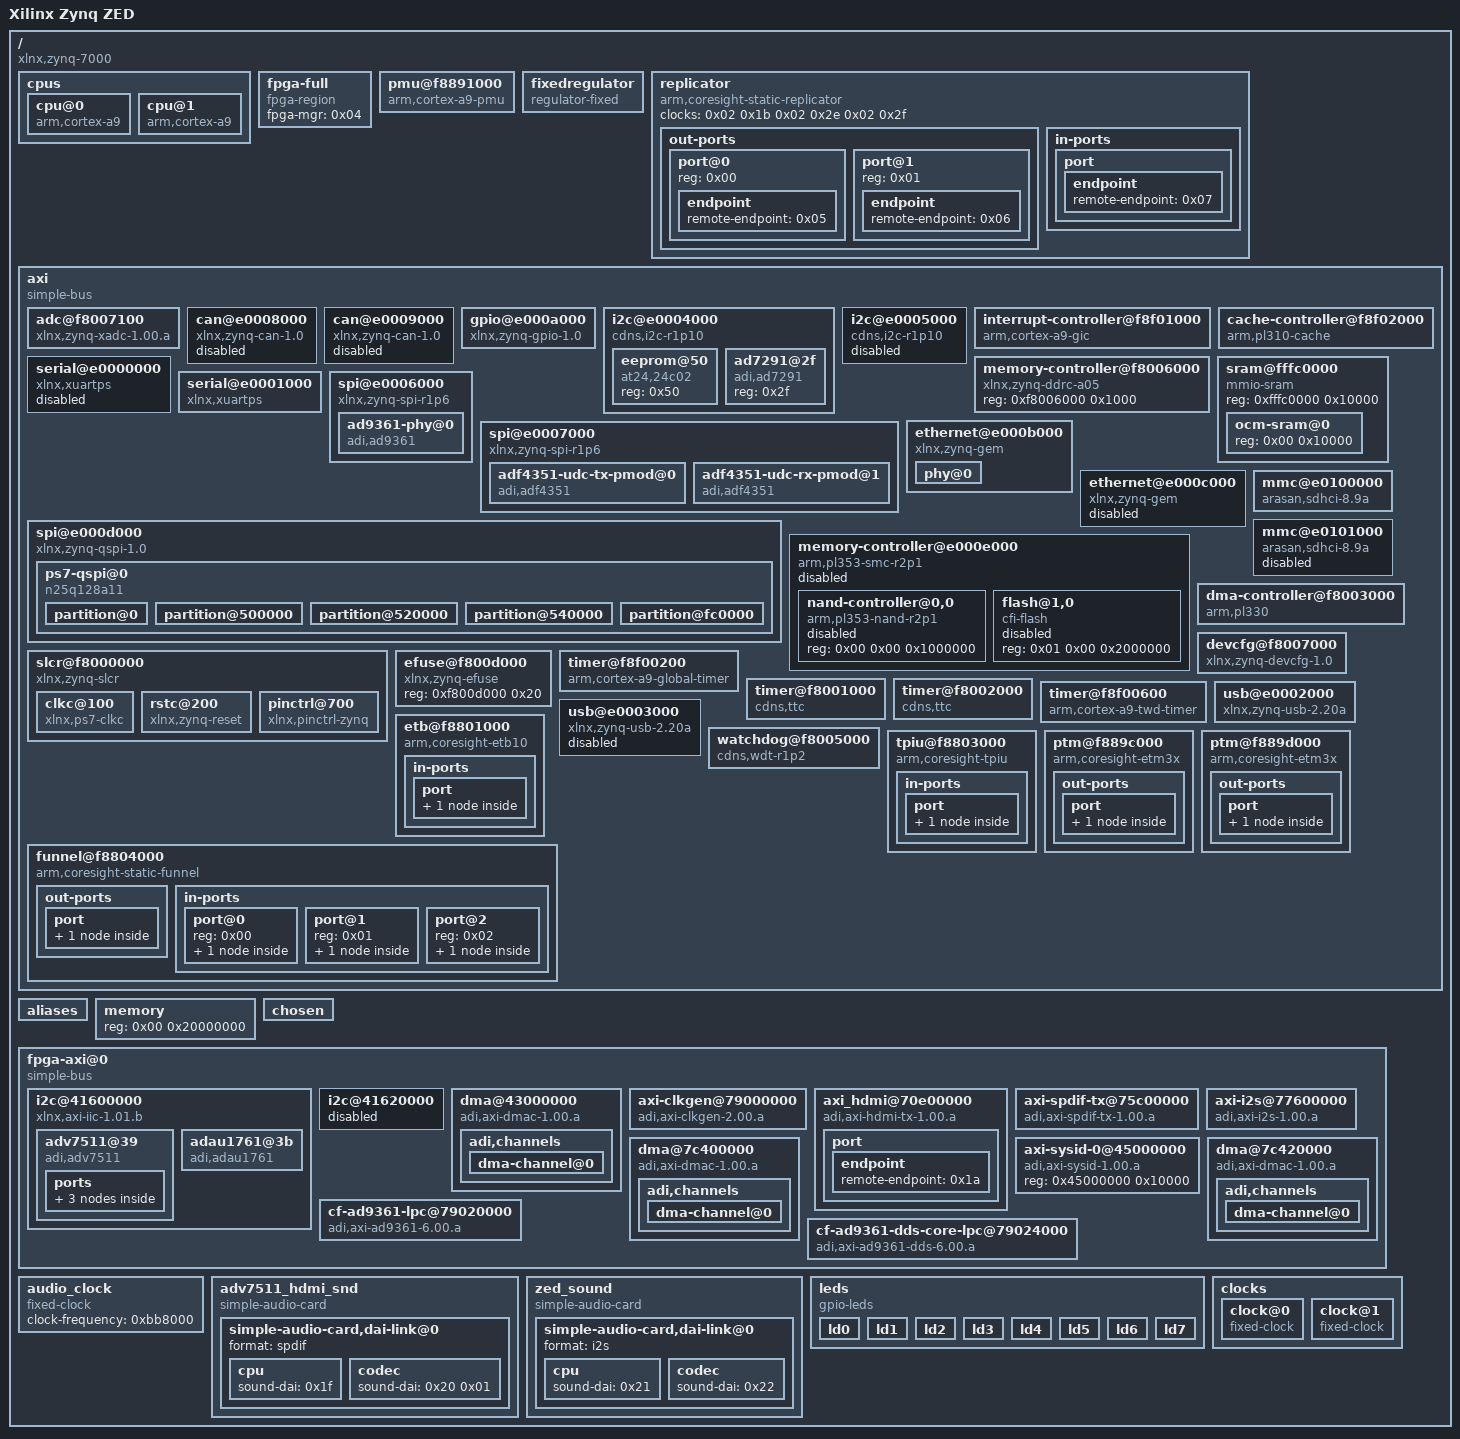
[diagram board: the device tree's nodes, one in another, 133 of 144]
/dts-v1/;

/ {
	#address-cells = <0x01>;
	#size-cells = <0x01>;
	compatible = "xlnx,zynq-7000";
	interrupt-parent = <0x01>;
	model = "Xilinx Zynq ZED";

	cpus {
		#address-cells = <0x01>;
		#size-cells = <0x00>;

		cpu@0 {
			compatible = "arm,cortex-a9";
			device_type = "cpu";
			reg = <0x00>;
			clocks = <0x02 0x03>;
			clock-latency = <0x3e8>;
			cpu0-supply = <0x03>;
			operating-points = <0xa2c2b 0xf4240 0x51616 0xf4240>;
			phandle = <0x12>;
		};

		cpu@1 {
			compatible = "arm,cortex-a9";
			device_type = "cpu";
			reg = <0x01>;
			clocks = <0x02 0x03>;
			phandle = <0x14>;
		};
	};

	fpga-full {
		compatible = "fpga-region";
		fpga-mgr = <0x04>;
		#address-cells = <0x01>;
		#size-cells = <0x01>;
		ranges;
		phandle = <0x23>;
	};

	pmu@f8891000 {
		compatible = "arm,cortex-a9-pmu";
		interrupts = <0x00 0x05 0x04 0x00 0x06 0x04>;
		interrupt-parent = <0x01>;
		reg = <0xf8891000 0x1000 0xf8893000 0x1000>;
	};

	fixedregulator {
		compatible = "regulator-fixed";
		regulator-name = "VCCPINT";
		regulator-min-microvolt = <0xf4240>;
		regulator-max-microvolt = <0xf4240>;
		regulator-boot-on;
		regulator-always-on;
		phandle = <0x03>;
	};

	replicator {
		compatible = "arm,coresight-static-replicator";
		clocks = <0x02 0x1b 0x02 0x2e 0x02 0x2f>;
		clock-names = "apb_pclk", "dbg_trc", "dbg_apb";

		out-ports {
			#address-cells = <0x01>;
			#size-cells = <0x00>;

			port@0 {
				reg = <0x00>;

				endpoint {
					remote-endpoint = <0x05>;
					phandle = <0x0e>;
				};
			};

			port@1 {
				reg = <0x01>;

				endpoint {
					remote-endpoint = <0x06>;
					phandle = <0x0d>;
				};
			};
		};

		in-ports {

			port {

				endpoint {
					remote-endpoint = <0x07>;
					phandle = <0x0f>;
				};
			};
		};
	};

	axi {
		u-boot,dm-pre-reloc;
		compatible = "simple-bus";
		#address-cells = <0x01>;
		#size-cells = <0x01>;
		interrupt-parent = <0x01>;
		ranges;
		phandle = <0x24>;

		adc@f8007100 {
			compatible = "xlnx,zynq-xadc-1.00.a";
			reg = <0xf8007100 0x20>;
			interrupts = <0x00 0x07 0x04>;
			interrupt-parent = <0x01>;
			clocks = <0x02 0x0c>;
			phandle = <0x25>;
		};

		can@e0008000 {
			compatible = "xlnx,zynq-can-1.0";
			status = "disabled";
			clocks = <0x02 0x13 0x02 0x24>;
			clock-names = "can_clk", "pclk";
			reg = <0xe0008000 0x1000>;
			interrupts = <0x00 0x1c 0x04>;
			interrupt-parent = <0x01>;
			tx-fifo-depth = <0x40>;
			rx-fifo-depth = <0x40>;
			phandle = <0x26>;
		};

		can@e0009000 {
			compatible = "xlnx,zynq-can-1.0";
			status = "disabled";
			clocks = <0x02 0x14 0x02 0x25>;
			clock-names = "can_clk", "pclk";
			reg = <0xe0009000 0x1000>;
			interrupts = <0x00 0x33 0x04>;
			interrupt-parent = <0x01>;
			tx-fifo-depth = <0x40>;
			rx-fifo-depth = <0x40>;
			phandle = <0x27>;
		};

		gpio@e000a000 {
			compatible = "xlnx,zynq-gpio-1.0";
			#gpio-cells = <0x02>;
			clocks = <0x02 0x2a>;
			gpio-controller;
			interrupt-controller;
			#interrupt-cells = <0x02>;
			interrupt-parent = <0x01>;
			interrupts = <0x00 0x14 0x04>;
			reg = <0xe000a000 0x1000>;
			phandle = <0x09>;
		};

	/*	i2c@e0004000 {
			compatible = "cdns,i2c-r1p10";
			status = "disabled";
			clocks = <0x02 0x26>;
			interrupt-parent = <0x01>;
			interrupts = <0x00 0x19 0x04>;
			clock-frequency = <0x61a80>;
			reg = <0xe0004000 0x1000>;
			#address-cells = <0x01>;
			#size-cells = <0x00>;
			phandle = <0x28>;
		}; */
            
                i2c@e0004000 {
                         compatible = "cdns,i2c-r1p10";
        		status = "okay";
        		clocks = <0x02 0x26>;
        		interrupt-parent = <0x01>;
        		interrupts = <0x00 0x19 0x04>;
        		clock-frequency = <100000>;
        		reg = <0xe0004000 0x1000>;
        		#address-cells = <0x01>;
       			 #size-cells = <0x00>;
        		phandle = <0x28>;

                      #address-cells = <1>;
                     #size-cells = <0>;

                      eeprom@50 {
                         compatible = "at24,24c02";
                         reg = <0x50>;
                         };

    			ad7291@2f {
      			  compatible = "adi,ad7291";
       			 reg = <0x2f>;
   			 };
			 };

		i2c@e0005000 {
			compatible = "cdns,i2c-r1p10";
			status = "disabled";
			clocks = <0x02 0x27>;
			interrupt-parent = <0x01>;
			interrupts = <0x00 0x30 0x04>;
			clock-frequency = <0x61a80>;
			reg = <0xe0005000 0x1000>;
			#address-cells = <0x01>;
			#size-cells = <0x00>;
			phandle = <0x29>;
		};

		interrupt-controller@f8f01000 {
			compatible = "arm,cortex-a9-gic";
			#interrupt-cells = <0x03>;
			interrupt-controller;
			reg = <0xf8f01000 0x1000 0xf8f00100 0x100>;
			phandle = <0x01>;
		};

		cache-controller@f8f02000 {
			compatible = "arm,pl310-cache";
			reg = <0xf8f02000 0x1000>;
			interrupts = <0x00 0x02 0x04>;
			arm,data-latency = <0x03 0x02 0x02>;
			arm,tag-latency = <0x02 0x02 0x02>;
			cache-unified;
			cache-level = <0x02>;
			phandle = <0x2a>;
		};

		memory-controller@f8006000 {
			compatible = "xlnx,zynq-ddrc-a05";
			reg = <0xf8006000 0x1000>;
			phandle = <0x2b>;
		};

		sram@fffc0000 {
			compatible = "mmio-sram";
			reg = <0xfffc0000 0x10000>;
			#address-cells = <0x01>;
			#size-cells = <0x01>;
			ranges = <0x00 0xfffc0000 0x10000>;
			phandle = <0x2c>;

			ocm-sram@0 {
				reg = <0x00 0x10000>;
			};
		};

		serial@e0000000 {
			compatible = "xlnx,xuartps", "cdns,uart-r1p8";
			status = "disabled";
			clocks = <0x02 0x17 0x02 0x28>;
			clock-names = "uart_clk", "pclk";
			reg = <0xe0000000 0x1000>;
			interrupts = <0x00 0x1b 0x04>;
			phandle = <0x2d>;
		};

		serial@e0001000 {
			compatible = "xlnx,xuartps", "cdns,uart-r1p8";
			status = "okay";
			clocks = <0x02 0x18 0x02 0x29>;
			clock-names = "uart_clk", "pclk";
			reg = <0xe0001000 0x1000>;
			interrupts = <0x00 0x32 0x04>;
			phandle = <0x2e>;
		};

		spi@e0006000 {
			compatible = "xlnx,zynq-spi-r1p6";
			reg = <0xe0006000 0x1000>;
			status = "okay";
			interrupt-parent = <0x01>;
			interrupts = <0x00 0x1a 0x04>;
			clocks = <0x02 0x19 0x02 0x22>;
			clock-names = "ref_clk", "pclk";
			#address-cells = <0x01>;
			#size-cells = <0x00>;
			phandle = <0x2f>;

			ad9361-phy@0 {
				compatible = "adi,ad9361";
				reg = <0x00>;
				spi-cpha;
				spi-max-frequency = <0x989680>;
				clocks = <0x08 0x00>;
				clock-names = "ad9361_ext_refclk";
				clock-output-names = "rx_sampl_clk", "tx_sampl_clk";
				#clock-cells = <0x01>;
				adi,digital-interface-tune-skip-mode = <0x00>;
				adi,pp-tx-swap-enable;
				adi,pp-rx-swap-enable;
				adi,rx-frame-pulse-mode-enable;
				adi,lvds-mode-enable;
				adi,lvds-bias-mV = <0x96>;
				adi,lvds-rx-onchip-termination-enable;
				adi,rx-data-delay = <0x04>;
				adi,tx-fb-clock-delay = <0x07>;
				adi,dcxo-coarse-and-fine-tune = <0x08 0x1720>;
				adi,2rx-2tx-mode-enable;
				adi,frequency-division-duplex-mode-enable;
				adi,rx-rf-port-input-select = <0x00>;
				adi,tx-rf-port-input-select = <0x00>;
				adi,tx-attenuation-mdB = <0x2710>;
				adi,tx-lo-powerdown-managed-enable;
				adi,rf-rx-bandwidth-hz = <0x112a880>;
				adi,rf-tx-bandwidth-hz = <0x112a880>;
				adi,rx-synthesizer-frequency-hz = <0x00 0x8f0d1800>;
				adi,tx-synthesizer-frequency-hz = <0x00 0x92080880>;
				adi,rx-path-clock-frequencies = <0x3a980000 0xea60000 0x7530000 0x3a98000 0x1d4c000 0x1d4c000>;
				adi,tx-path-clock-frequencies = <0x3a980000 0x7530000 0x7530000 0x3a98000 0x1d4c000 0x1d4c000>;
				adi,gc-rx1-mode = <0x02>;
				adi,gc-rx2-mode = <0x02>;
				adi,gc-adc-ovr-sample-size = <0x04>;
				adi,gc-adc-small-overload-thresh = <0x2f>;
				adi,gc-adc-large-overload-thresh = <0x3a>;
				adi,gc-lmt-overload-high-thresh = <0x320>;
				adi,gc-lmt-overload-low-thresh = <0x2c0>;
				adi,gc-dec-pow-measurement-duration = <0x2000>;
				adi,gc-low-power-thresh = <0x18>;
				adi,mgc-inc-gain-step = <0x02>;
				adi,mgc-dec-gain-step = <0x02>;
				adi,mgc-split-table-ctrl-inp-gain-mode = <0x00>;
				adi,agc-attack-delay-extra-margin-us = <0x01>;
				adi,agc-outer-thresh-high = <0x05>;
				adi,agc-outer-thresh-high-dec-steps = <0x02>;
				adi,agc-inner-thresh-high = <0x0a>;
				adi,agc-inner-thresh-high-dec-steps = <0x01>;
				adi,agc-inner-thresh-low = <0x0c>;
				adi,agc-inner-thresh-low-inc-steps = <0x01>;
				adi,agc-outer-thresh-low = <0x12>;
				adi,agc-outer-thresh-low-inc-steps = <0x02>;
				adi,agc-adc-small-overload-exceed-counter = <0x0a>;
				adi,agc-adc-large-overload-exceed-counter = <0x0a>;
				adi,agc-adc-large-overload-inc-steps = <0x02>;
				adi,agc-lmt-overload-large-exceed-counter = <0x0a>;
				adi,agc-lmt-overload-small-exceed-counter = <0x0a>;
				adi,agc-lmt-overload-large-inc-steps = <0x02>;
				adi,agc-gain-update-interval-us = <0x3e8>;
				adi,fagc-dec-pow-measurement-duration = <0x40>;
				adi,fagc-lp-thresh-increment-steps = <0x01>;
				adi,fagc-lp-thresh-increment-time = <0x05>;
				adi,fagc-energy-lost-stronger-sig-gain-lock-exit-cnt = <0x08>;
				adi,fagc-final-overrange-count = <0x03>;
				adi,fagc-gain-index-type-after-exit-rx-mode = <0x00>;
				adi,fagc-lmt-final-settling-steps = <0x01>;
				adi,fagc-lock-level = <0x0a>;
				adi,fagc-lock-level-gain-increase-upper-limit = <0x05>;
				adi,fagc-lock-level-lmt-gain-increase-enable;
				adi,fagc-lpf-final-settling-steps = <0x01>;
				adi,fagc-optimized-gain-offset = <0x05>;
				adi,fagc-power-measurement-duration-in-state5 = <0x40>;
				adi,fagc-rst-gla-engergy-lost-goto-optim-gain-enable;
				adi,fagc-rst-gla-engergy-lost-sig-thresh-below-ll = <0x0a>;
				adi,fagc-rst-gla-engergy-lost-sig-thresh-exceeded-enable;
				adi,fagc-rst-gla-if-en-agc-pulled-high-mode = <0x00>;
				adi,fagc-rst-gla-large-adc-overload-enable;
				adi,fagc-rst-gla-large-lmt-overload-enable;
				adi,fagc-rst-gla-stronger-sig-thresh-above-ll = <0x0a>;
				adi,fagc-rst-gla-stronger-sig-thresh-exceeded-enable;
				adi,fagc-state-wait-time-ns = <0x104>;
				adi,fagc-use-last-lock-level-for-set-gain-enable;
				adi,rssi-restart-mode = <0x03>;
				adi,rssi-delay = <0x01>;
				adi,rssi-wait = <0x01>;
				adi,rssi-duration = <0x3e8>;
				adi,ctrl-outs-index = <0x00>;
				adi,ctrl-outs-enable-mask = <0xff>;
				adi,temp-sense-measurement-interval-ms = <0x3e8>;
				adi,temp-sense-offset-signed = <0xce>;
				adi,temp-sense-periodic-measurement-enable;
				adi,aux-dac-manual-mode-enable;
				adi,aux-dac1-default-value-mV = <0x00>;
				adi,aux-dac1-rx-delay-us = <0x00>;
				adi,aux-dac1-tx-delay-us = <0x00>;
				adi,aux-dac2-default-value-mV = <0x00>;
				adi,aux-dac2-rx-delay-us = <0x00>;
				adi,aux-dac2-tx-delay-us = <0x00>;
				en_agc-gpios = <0x09 0x62 0x00>;
				sync-gpios = <0x09 0x63 0x00>;
				reset-gpios = <0x09 0x64 0x00>;
				enable-gpios = <0x09 0x65 0x00>;
				txnrx-gpios = <0x09 0x66 0x00>;
				phandle = <0x1d>;
			};
		};

		spi@e0007000 {
			compatible = "xlnx,zynq-spi-r1p6";
			reg = <0xe0007000 0x1000>;
			status = "okay";
			interrupt-parent = <0x01>;
			interrupts = <0x00 0x31 0x04>;
			clocks = <0x02 0x1a 0x02 0x23>;
			clock-names = "ref_clk", "pclk";
			#address-cells = <0x01>;
			#size-cells = <0x00>;
			phandle = <0x30>;

			adf4351-udc-tx-pmod@0 {
				compatible = "adi,adf4351";
				reg = <0x00>;
				spi-max-frequency = <0x989680>;
				clocks = <0x0a>;
				clock-names = "clkin";
				adi,channel-spacing = <0xf4240>;
				adi,power-up-frequency = <0x160dc080>;
				adi,phase-detector-polarity-positive-enable;
				adi,charge-pump-current = <0x9c4>;
				adi,output-power = <0x03>;
				adi,mute-till-lock-enable;
				adi,muxout-select = <0x06>;
				gpios = <0x09 0x68 0x00>;
				phandle = <0x31>;
			};

			adf4351-udc-rx-pmod@1 {
				compatible = "adi,adf4351";
				reg = <0x01>;
				spi-max-frequency = <0x989680>;
				clocks = <0x0a>;
				clock-names = "clkin";
				adi,channel-spacing = <0xf4240>;
				adi,power-up-frequency = <0x1443fd00>;
				adi,phase-detector-polarity-positive-enable;
				adi,charge-pump-current = <0x9c4>;
				adi,output-power = <0x03>;
				adi,mute-till-lock-enable;
				adi,muxout-select = <0x06>;
				gpios = <0x09 0x67 0x00>;
				phandle = <0x32>;
			};
		};

		spi@e000d000 {
			compatible = "xlnx,zynq-qspi-1.0";
			reg = <0xe000d000 0x1000>;
			interrupt-parent = <0x01>;
			interrupts = <0x00 0x13 0x04>;
			clocks = <0x02 0x0a 0x02 0x2b>;
			clock-names = "ref_clk", "pclk";
			status = "okay";
			#address-cells = <0x01>;
			#size-cells = <0x00>;
			is-dual = <0x00>;
			num-cs = <0x01>;
			phandle = <0x33>;

			ps7-qspi@0 {
				#address-cells = <0x01>;
				#size-cells = <0x01>;
				compatible = "n25q128a11";
				reg = <0x00>;
				spi-max-frequency = <0x2faf080>;
				phandle = <0x34>;

				partition@0 {
					label = "boot";
					reg = <0x00 0x500000>;
				};

				partition@500000 {
					label = "bootenv";
					reg = <0x500000 0x20000>;
				};

				partition@520000 {
					label = "config";
					reg = <0x520000 0x20000>;
				};

				partition@540000 {
					label = "image";
					reg = <0x540000 0xa80000>;
				};

				partition@fc0000 {
					label = "spare";
					reg = <0xfc0000 0x00>;
				};
			};
		};

		ethernet@e000b000 {
			compatible = "xlnx,zynq-gem", "cdns,gem";
			reg = <0xe000b000 0x1000>;
			status = "okay";
			interrupts = <0x00 0x16 0x04>;
			clocks = <0x02 0x1e 0x02 0x1e 0x02 0x0d>;
			clock-names = "pclk", "hclk", "tx_clk";
			#address-cells = <0x01>;
			#size-cells = <0x00>;
			phy-handle = <0x0b>;
			phy-mode = "rgmii-id";
			phandle = <0x35>;

			phy@0 {
				device_type = "ethernet-phy";
				reg = <0x00>;
				marvell,reg-init = <0x03 0x10 0xff00 0x1e 0x03 0x11 0xfff0 0x0a>;
				phandle = <0x0b>;
			};
		};

		ethernet@e000c000 {
			compatible = "xlnx,zynq-gem", "cdns,gem";
			reg = <0xe000c000 0x1000>;
			status = "disabled";
			interrupts = <0x00 0x2d 0x04>;
			clocks = <0x02 0x1f 0x02 0x1f 0x02 0x0e>;
			clock-names = "pclk", "hclk", "tx_clk";
			#address-cells = <0x01>;
			#size-cells = <0x00>;
			phandle = <0x36>;
		};

		memory-controller@e000e000 {
			compatible = "arm,pl353-smc-r2p1", "arm,primecell";
			reg = <0xe000e000 0x1000>;
			status = "disabled";
			clock-names = "memclk", "apb_pclk";
			clocks = <0x02 0x0b 0x02 0x2c>;
			ranges = <0x00 0x00 0xe1000000 0x1000000 0x01 0x00 0xe2000000 0x2000000 0x02 0x00 0xe4000000 0x2000000>;
			#address-cells = <0x02>;
			#size-cells = <0x01>;
			interrupt-parent = <0x01>;
			interrupts = <0x00 0x12 0x04>;
			phandle = <0x37>;

			nand-controller@0,0 {
				compatible = "arm,pl353-nand-r2p1";
				reg = <0x00 0x00 0x1000000>;
				status = "disabled";
				#address-cells = <0x01>;
				#size-cells = <0x00>;
				phandle = <0x38>;
			};

			flash@1,0 {
				status = "disabled";
				compatible = "cfi-flash";
				reg = <0x01 0x00 0x2000000>;
				#address-cells = <0x01>;
				#size-cells = <0x01>;
				phandle = <0x39>;
			};
		};

		mmc@e0100000 {
			compatible = "arasan,sdhci-8.9a";
			status = "okay";
			clock-names = "clk_xin", "clk_ahb";
			clocks = <0x02 0x15 0x02 0x20>;
			interrupt-parent = <0x01>;
			interrupts = <0x00 0x18 0x04>;
			reg = <0xe0100000 0x1000>;
			phandle = <0x3a>;
		};

		mmc@e0101000 {
			compatible = "arasan,sdhci-8.9a";
			status = "disabled";
			clock-names = "clk_xin", "clk_ahb";
			clocks = <0x02 0x16 0x02 0x21>;
			interrupt-parent = <0x01>;
			interrupts = <0x00 0x2f 0x04>;
			reg = <0xe0101000 0x1000>;
			phandle = <0x3b>;
		};

		slcr@f8000000 {
			u-boot,dm-pre-reloc;
			#address-cells = <0x01>;
			#size-cells = <0x01>;
			compatible = "xlnx,zynq-slcr", "syscon", "simple-mfd";
			reg = <0xf8000000 0x1000>;
			ranges;
			phandle = <0x0c>;

			clkc@100 {
				u-boot,dm-pre-reloc;
				#clock-cells = <0x01>;
				compatible = "xlnx,ps7-clkc";
				fclk-enable = <0x0f>;
				clock-output-names = "armpll", "ddrpll", "iopll", "cpu_6or4x", "cpu_3or2x", "cpu_2x", "cpu_1x", "ddr2x", "ddr3x", "dci", "lqspi", "smc", "pcap", "gem0", "gem1", "fclk0", "fclk1", "fclk2", "fclk3", "can0", "can1", "sdio0", "sdio1", "uart0", "uart1", "spi0", "spi1", "dma", "usb0_aper", "usb1_aper", "gem0_aper", "gem1_aper", "sdio0_aper", "sdio1_aper", "spi0_aper", "spi1_aper", "can0_aper", "can1_aper", "i2c0_aper", "i2c1_aper", "uart0_aper", "uart1_aper", "gpio_aper", "lqspi_aper", "smc_aper", "swdt", "dbg_trc", "dbg_apb";
				reg = <0x100 0x100>;
				ps-clk-frequency = <0x1fca055>;
				phandle = <0x02>;
			};

			rstc@200 {
				compatible = "xlnx,zynq-reset";
				reg = <0x200 0x48>;
				#reset-cells = <0x01>;
				syscon = <0x0c>;
				phandle = <0x3c>;
			};

			pinctrl@700 {
				compatible = "xlnx,pinctrl-zynq";
				reg = <0x700 0x200>;
				syscon = <0x0c>;
				phandle = <0x3d>;
			};
		};

		dma-controller@f8003000 {
			compatible = "arm,pl330", "arm,primecell";
			reg = <0xf8003000 0x1000>;
			interrupt-parent = <0x01>;
			interrupts = <0x00 0x0d 0x04 0x00 0x0e 0x04 0x00 0x0f 0x04 0x00 0x10 0x04 0x00 0x11 0x04 0x00 0x28 0x04 0x00 0x29 0x04 0x00 0x2a 0x04 0x00 0x2b 0x04>;
			#dma-cells = <0x01>;
			clocks = <0x02 0x1b>;
			clock-names = "apb_pclk";
			phandle = <0x1b>;
		};

		devcfg@f8007000 {
			compatible = "xlnx,zynq-devcfg-1.0";
			reg = <0xf8007000 0x100>;
			interrupt-parent = <0x01>;
			interrupts = <0x00 0x08 0x04>;
			clocks = <0x02 0x0c 0x02 0x0f 0x02 0x10 0x02 0x11 0x02 0x12>;
			clock-names = "ref_clk", "fclk0", "fclk1", "fclk2", "fclk3";
			syscon = <0x0c>;
			phandle = <0x04>;
		};

		efuse@f800d000 {
			compatible = "xlnx,zynq-efuse";
			reg = <0xf800d000 0x20>;
			phandle = <0x3e>;
		};

		timer@f8f00200 {
			compatible = "arm,cortex-a9-global-timer";
			reg = <0xf8f00200 0x20>;
			interrupts = <0x01 0x0b 0x301>;
			interrupt-parent = <0x01>;
			clocks = <0x02 0x04>;
			phandle = <0x3f>;
		};

		timer@f8001000 {
			interrupt-parent = <0x01>;
			interrupts = <0x00 0x0a 0x04 0x00 0x0b 0x04 0x00 0x0c 0x04>;
			compatible = "cdns,ttc";
			clocks = <0x02 0x06>;
			reg = <0xf8001000 0x1000>;
			phandle = <0x40>;
		};

		timer@f8002000 {
			interrupt-parent = <0x01>;
			interrupts = <0x00 0x25 0x04 0x00 0x26 0x04 0x00 0x27 0x04>;
			compatible = "cdns,ttc";
			clocks = <0x02 0x06>;
			reg = <0xf8002000 0x1000>;
			phandle = <0x41>;
		};

		timer@f8f00600 {
			u-boot,dm-pre-reloc;
			interrupt-parent = <0x01>;
			interrupts = <0x01 0x0d 0x301>;
			compatible = "arm,cortex-a9-twd-timer";
			reg = <0xf8f00600 0x20>;
			clocks = <0x02 0x04>;
			phandle = <0x42>;
		};

		usb@e0002000 {
			compatible = "xlnx,zynq-usb-2.20a", "chipidea,usb2";
			status = "okay";
			clocks = <0x02 0x1c>;
			interrupt-parent = <0x01>;
			interrupts = <0x00 0x15 0x04>;
			reg = <0xe0002000 0x1000>;
			phy_type = "ulpi";
			dr_mode = "host";
			xlnx,phy-reset-gpio = <0x09 0x55 0x00>;
			phandle = <0x43>;
		};

		usb@e0003000 {
			compatible = "xlnx,zynq-usb-2.20a", "chipidea,usb2";
			status = "disabled";
			clocks = <0x02 0x1d>;
			interrupt-parent = <0x01>;
			interrupts = <0x00 0x2c 0x04>;
			reg = <0xe0003000 0x1000>;
			phy_type = "ulpi";
			phandle = <0x44>;
		};

		watchdog@f8005000 {
			clocks = <0x02 0x2d>;
			compatible = "cdns,wdt-r1p2";
			interrupt-parent = <0x01>;
			interrupts = <0x00 0x09 0x01>;
			reg = <0xf8005000 0x1000>;
			timeout-sec = <0x0a>;
			phandle = <0x45>;
		};

		etb@f8801000 {
			compatible = "arm,coresight-etb10", "arm,primecell";
			reg = <0xf8801000 0x1000>;
			clocks = <0x02 0x1b 0x02 0x2e 0x02 0x2f>;
			clock-names = "apb_pclk", "dbg_trc", "dbg_apb";

			in-ports {

				port {

					endpoint {
						remote-endpoint = <0x0d>;
						phandle = <0x06>;
					};
				};
			};
		};

		tpiu@f8803000 {
			compatible = "arm,coresight-tpiu", "arm,primecell";
			reg = <0xf8803000 0x1000>;
			clocks = <0x02 0x1b 0x02 0x2e 0x02 0x2f>;
			clock-names = "apb_pclk", "dbg_trc", "dbg_apb";

			in-ports {

				port {

					endpoint {
						remote-endpoint = <0x0e>;
						phandle = <0x05>;
					};
				};
			};
		};

		funnel@f8804000 {
			compatible = "arm,coresight-static-funnel", "arm,primecell";
			reg = <0xf8804000 0x1000>;
			clocks = <0x02 0x1b 0x02 0x2e 0x02 0x2f>;
			clock-names = "apb_pclk", "dbg_trc", "dbg_apb";

			out-ports {

				port {

					endpoint {
						remote-endpoint = <0x0f>;
						phandle = <0x07>;
					};
				};
			};

			in-ports {
				#address-cells = <0x01>;
				#size-cells = <0x00>;

				port@0 {
					reg = <0x00>;

					endpoint {
						remote-endpoint = <0x10>;
						phandle = <0x13>;
					};
				};

				port@1 {
					reg = <0x01>;

					endpoint {
						remote-endpoint = <0x11>;
						phandle = <0x15>;
					};
				};

				port@2 {
					reg = <0x02>;

					endpoint {
						phandle = <0x46>;
					};
				};
			};
		};

		ptm@f889c000 {
			compatible = "arm,coresight-etm3x", "arm,primecell";
			reg = <0xf889c000 0x1000>;
			clocks = <0x02 0x1b 0x02 0x2e 0x02 0x2f>;
			clock-names = "apb_pclk", "dbg_trc", "dbg_apb";
			cpu = <0x12>;

			out-ports {

				port {

					endpoint {
						remote-endpoint = <0x13>;
						phandle = <0x10>;
					};
				};
			};
		};

		ptm@f889d000 {
			compatible = "arm,coresight-etm3x", "arm,primecell";
			reg = <0xf889d000 0x1000>;
			clocks = <0x02 0x1b 0x02 0x2e 0x02 0x2f>;
			clock-names = "apb_pclk", "dbg_trc", "dbg_apb";
			cpu = <0x14>;

			out-ports {

				port {

					endpoint {
						remote-endpoint = <0x15>;
						phandle = <0x11>;
					};
				};
			};
		};
	};

	aliases {
		ethernet0 = "/axi/ethernet@e000b000";
		serial0 = "/axi/serial@e0001000";
		phandle = <0x47>;
	};

	memory {
		device_type = "memory";
		reg = <0x00 0x20000000>;
	};

	chosen {
		bootargs = "console=ttyPS0,115200 root=/dev/mmcblk0p2 rw earlyprintk rootfstype=ext4 rootwait";
		stdout-path = "/amba@0/uart@E0001000";
	};

	fpga-axi@0 {
		compatible = "simple-bus";
		#address-cells = <0x01>;
		#size-cells = <0x01>;
		ranges;
		phandle = <0x48>;

		i2c@41600000 {
			compatible = "xlnx,axi-iic-1.01.b", "xlnx,xps-iic-2.00.a";
			reg = <0x41600000 0x10000>;
			interrupt-parent = <0x01>;
			interrupts = <0x00 0x3a 0x04>;
			clocks = <0x02 0x0f>;
			clock-names = "pclk";
			#size-cells = <0x00>;
			#address-cells = <0x01>;

			adv7511@39 {
				compatible = "adi,adv7511";
				reg = <0x39 0x3f>;
				reg-names = "primary", "edid";
				adi,input-depth = <0x08>;
				adi,input-colorspace = "yuv422";
				adi,input-clock = "1x";
				adi,input-style = <0x01>;
				adi,input-justification = "right";
				adi,clock-delay = <0x00>;
				#sound-dai-cells = <0x01>;
				phandle = <0x20>;

				ports {
					#address-cells = <0x01>;
					#size-cells = <0x00>;

					port@0 {
						reg = <0x00>;

						endpoint {
							remote-endpoint = <0x16>;
							phandle = <0x1a>;
						};
					};

					port@1 {
						reg = <0x01>;
					};
				};
			};

			adau1761@3b {
				compatible = "adi,adau1761";
				reg = <0x3b>;
				clocks = <0x17>;
				clock-names = "mclk";
				#sound-dai-cells = <0x00>;
				phandle = <0x22>;
			};
		};

	/*	i2c@41620000 {
			compatible = "xlnx,axi-iic-1.01.b", "xlnx,xps-iic-2.00.a";
			reg = <0x41620000 0x10000>;
			interrupt-parent = <0x01>;
			interrupts = <0x00 0x37 0x04>;
			clocks = <0x02 0x0f>;
			clock-names = "pclk";
			#size-cells = <0x00>;
			#address-cells = <0x01>;
			phandle = <0x49>;

			eeprom@50 {
				compatible = "at24,24c02";
				reg = <0x50>;
				phandle = <0x4a>;
			};

			ad7291@2f {
				compatible = "adi,ad7291";
				reg = <0x2f>;
			};
		}; */
                
    				i2c@41620000 {
        			status = "disabled";
  				 };
				

		dma@43000000 {
			compatible = "adi,axi-dmac-1.00.a";
			reg = <0x43000000 0x1000>;
			#dma-cells = <0x01>;
			interrupts = <0x00 0x3b 0x04>;
			clocks = <0x02 0x10>;
			phandle = <0x18>;

			adi,channels {
				#size-cells = <0x00>;
				#address-cells = <0x01>;

				dma-channel@0 {
					reg = <0x00>;
					adi,source-bus-width = <0x40>;
					adi,source-bus-type = <0x00>;
					adi,destination-bus-width = <0x40>;
					adi,destination-bus-type = <0x01>;
				};
			};
		};

		axi-clkgen@79000000 {
			compatible = "adi,axi-clkgen-2.00.a";
			reg = <0x79000000 0x10000>;
			#clock-cells = <0x00>;
			clocks = <0x02 0x0f 0x02 0x10>;
			clock-names = "s_axi_aclk", "clkin1";
			phandle = <0x19>;
		};

		axi_hdmi@70e00000 {
			compatible = "adi,axi-hdmi-tx-1.00.a";
			reg = <0x70e00000 0x10000>;
			dmas = <0x18 0x00>;
			dma-names = "video";
			clocks = <0x19>;

			port {

				endpoint {
					remote-endpoint = <0x1a>;
					phandle = <0x16>;
				};
			};
		};

		axi-spdif-tx@75c00000 {
			compatible = "adi,axi-spdif-tx-1.00.a";
			reg = <0x75c00000 0x1000>;
			dmas = <0x1b 0x00>;
			dma-names = "tx";
			clocks = <0x02 0x0f 0x17>;
			clock-names = "axi", "ref";
			#sound-dai-cells = <0x00>;
			phandle = <0x1f>;
		};

		axi-i2s@77600000 {
			compatible = "adi,axi-i2s-1.00.a";
			reg = <0x77600000 0x1000>;
			dmas = <0x1b 0x01 0x1b 0x02>;
			dma-names = "tx", "rx";
			clocks = <0x02 0x0f 0x17>;
			clock-names = "axi", "ref";
			#sound-dai-cells = <0x00>;
			phandle = <0x21>;
		};

		axi-sysid-0@45000000 {
			compatible = "adi,axi-sysid-1.00.a";
			reg = <0x45000000 0x10000>;
			phandle = <0x4b>;
		};

		dma@7c400000 {
			compatible = "adi,axi-dmac-1.00.a";
			reg = <0x7c400000 0x1000>;
			#dma-cells = <0x01>;
			interrupts = <0x00 0x39 0x04>;
			clocks = <0x02 0x10>;
			phandle = <0x1c>;

			adi,channels {
				#size-cells = <0x00>;
				#address-cells = <0x01>;

				dma-channel@0 {
					reg = <0x00>;
					adi,source-bus-width = <0x40>;
					adi,source-bus-type = <0x02>;
					adi,destination-bus-width = <0x40>;
					adi,destination-bus-type = <0x00>;
				};
			};
		};

		dma@7c420000 {
			compatible = "adi,axi-dmac-1.00.a";
			reg = <0x7c420000 0x1000>;
			#dma-cells = <0x01>;
			interrupts = <0x00 0x38 0x04>;
			clocks = <0x02 0x10>;
			phandle = <0x1e>;

			adi,channels {
				#size-cells = <0x00>;
				#address-cells = <0x01>;

				dma-channel@0 {
					reg = <0x00>;
					adi,source-bus-width = <0x40>;
					adi,source-bus-type = <0x00>;
					adi,destination-bus-width = <0x40>;
					adi,destination-bus-type = <0x02>;
				};
			};
		};

		cf-ad9361-lpc@79020000 {
			compatible = "adi,axi-ad9361-6.00.a";
			reg = <0x79020000 0x6000>;
			dmas = <0x1c 0x00>;
			dma-names = "rx";
			spibus-connected = <0x1d>;
			phandle = <0x4c>;
		};

		cf-ad9361-dds-core-lpc@79024000 {
			compatible = "adi,axi-ad9361-dds-6.00.a";
			reg = <0x79024000 0x1000>;
			clocks = <0x1d 0x0d>;
			clock-names = "sampl_clk";
			dmas = <0x1e 0x00>;
			dma-names = "tx";
			phandle = <0x4d>;
		};
	};

	audio_clock {
		compatible = "fixed-clock";
		#clock-cells = <0x00>;
		clock-frequency = <0xbb8000>;
		phandle = <0x17>;
	};

	adv7511_hdmi_snd {
		compatible = "simple-audio-card";
		simple-audio-card,name = "HDMI monitor";
		simple-audio-card,widgets = "Speaker", "Speaker";
		simple-audio-card,routing = "Speaker", "TX";

		simple-audio-card,dai-link@0 {
			format = "spdif";

			cpu {
				sound-dai = <0x1f>;
			};

			codec {
				sound-dai = <0x20 0x01>;
			};
		};
	};

	zed_sound {
		compatible = "simple-audio-card";
		simple-audio-card,name = "ZED ADAU1761";
		simple-audio-card,widgets = "Microphone", "Mic In", "Headphone", "Headphone Out", "Line", "Line In", "Line", "Line Out";
		simple-audio-card,routing = "Line Out", "LOUT", "Line Out", "ROUT", "Headphone Out", "LHP", "Headphone Out", "RHP", "Mic In", "MICBIAS", "LINN", "Mic In", "RINN", "Mic In", "LAUX", "Line In", "RAUX", "Line In";

		simple-audio-card,dai-link@0 {
			format = "i2s";

			cpu {
				sound-dai = <0x21>;
			};

			codec {
				sound-dai = <0x22>;
			};
		};
	};

	leds {
		compatible = "gpio-leds";

		ld0 {
			label = "ld0:red";
			gpios = <0x09 0x49 0x00>;
		};

		ld1 {
			label = "ld1:red";
			gpios = <0x09 0x4a 0x00>;
		};

		ld2 {
			label = "ld2:red";
			gpios = <0x09 0x4b 0x00>;
		};

		ld3 {
			label = "ld3:red";
			gpios = <0x09 0x4c 0x00>;
		};

		ld4 {
			label = "ld4:red";
			gpios = <0x09 0x4d 0x00>;
		};

		ld5 {
			label = "ld5:red";
			gpios = <0x09 0x4e 0x00>;
		};

		ld6 {
			label = "ld6:red";
			gpios = <0x09 0x4f 0x00>;
		};

		ld7 {
			label = "ld7:red";
			gpios = <0x09 0x50 0x00>;
		};
	};

	clocks {

		clock@0 {
			compatible = "fixed-clock";
			clock-frequency = <0x2625a00>;
			clock-output-names = "ad9361_ext_refclk";
			#clock-cells = <0x00>;
			phandle = <0x08>;
		};

		clock@1 {
			compatible = "fixed-clock";
			clock-frequency = <0x17d7840>;
			clock-output-names = "refclk";
			#clock-cells = <0x00>;
			phandle = <0x0a>;
		};
	};

	__symbols__ {
		cpu0 = "/cpus/cpu@0";
		cpu1 = "/cpus/cpu@1";
		fpga_full = "/fpga-full";
		regulator_vccpint = "/fixedregulator";
		replicator_out_port0 = "/replicator/out-ports/port@0/endpoint";
		replicator_out_port1 = "/replicator/out-ports/port@1/endpoint";
		replicator_in_port0 = "/replicator/in-ports/port/endpoint";
		amba = "/axi";
		adc = "/axi/adc@f8007100";
		can0 = "/axi/can@e0008000";
		can1 = "/axi/can@e0009000";
		gpio0 = "/axi/gpio@e000a000";
		i2c0 = "/axi/i2c@e0004000";
		i2c1 = "/axi/i2c@e0005000";
		intc = "/axi/interrupt-controller@f8f01000";
		L2 = "/axi/cache-controller@f8f02000";
		mc = "/axi/memory-controller@f8006000";
		ocm = "/axi/sram@fffc0000";
		uart0 = "/axi/serial@e0000000";
		uart1 = "/axi/serial@e0001000";
		spi0 = "/axi/spi@e0006000";
		adc0_ad9361 = "/axi/spi@e0006000/ad9361-phy@0";
		spi1 = "/axi/spi@e0007000";
		lo_pll0_tx_adf4351 = "/axi/spi@e0007000/adf4351-udc-tx-pmod@0";
		lo_pll0_rx_adf4351 = "/axi/spi@e0007000/adf4351-udc-rx-pmod@1";
		qspi = "/axi/spi@e000d000";
		primary_flash = "/axi/spi@e000d000/ps7-qspi@0";
		gem0 = "/axi/ethernet@e000b000";
		phy0 = "/axi/ethernet@e000b000/phy@0";
		gem1 = "/axi/ethernet@e000c000";
		smcc = "/axi/memory-controller@e000e000";
		nfc0 = "/axi/memory-controller@e000e000/nand-controller@0,0";
		nor0 = "/axi/memory-controller@e000e000/flash@1,0";
		sdhci0 = "/axi/mmc@e0100000";
		sdhci1 = "/axi/mmc@e0101000";
		slcr = "/axi/slcr@f8000000";
		clkc = "/axi/slcr@f8000000/clkc@100";
		rstc = "/axi/slcr@f8000000/rstc@200";
		pinctrl0 = "/axi/slcr@f8000000/pinctrl@700";
		dmac_s = "/axi/dma-controller@f8003000";
		devcfg = "/axi/devcfg@f8007000";
		efuse = "/axi/efuse@f800d000";
		global_timer = "/axi/timer@f8f00200";
		ttc0 = "/axi/timer@f8001000";
		ttc1 = "/axi/timer@f8002000";
		scutimer = "/axi/timer@f8f00600";
		usb0 = "/axi/usb@e0002000";
		usb1 = "/axi/usb@e0003000";
		watchdog0 = "/axi/watchdog@f8005000";
		etb_in_port = "/axi/etb@f8801000/in-ports/port/endpoint";
		tpiu_in_port = "/axi/tpiu@f8803000/in-ports/port/endpoint";
		funnel_out_port = "/axi/funnel@f8804000/out-ports/port/endpoint";
		funnel0_in_port0 = "/axi/funnel@f8804000/in-ports/port@0/endpoint";
		funnel0_in_port1 = "/axi/funnel@f8804000/in-ports/port@1/endpoint";
		funnel0_in_port2 = "/axi/funnel@f8804000/in-ports/port@2/endpoint";
		ptm0_out_port = "/axi/ptm@f889c000/out-ports/port/endpoint";
		ptm1_out_port = "/axi/ptm@f889d000/out-ports/port/endpoint";
		aliases = "/aliases";
		fpga_axi = "/fpga-axi@0";
		adv7511 = "/fpga-axi@0/i2c@41600000/adv7511@39";
		adv7511_in = "/fpga-axi@0/i2c@41600000/adv7511@39/ports/port@0/endpoint";
		adau1761 = "/fpga-axi@0/i2c@41600000/adau1761@3b";
		fmc_i2c = "/fpga-axi@0/i2c@41620000";
		eeprom1 = "/fpga-axi@0/i2c@41620000/eeprom@50";
		hdmi_dma = "/fpga-axi@0/dma@43000000";
		hdmi_clock = "/fpga-axi@0/axi-clkgen@79000000";
		axi_hdmi_out = "/fpga-axi@0/axi_hdmi@70e00000/port/endpoint";
		axi_spdif_tx_0 = "/fpga-axi@0/axi-spdif-tx@75c00000";
		axi_i2s_0 = "/fpga-axi@0/axi-i2s@77600000";
		axi_sysid_0 = "/fpga-axi@0/axi-sysid-0@45000000";
		rx_dma = "/fpga-axi@0/dma@7c400000";
		tx_dma = "/fpga-axi@0/dma@7c420000";
		cf_ad9361_adc_core_0 = "/fpga-axi@0/cf-ad9361-lpc@79020000";
		cf_ad9361_dac_core_0 = "/fpga-axi@0/cf-ad9361-dds-core-lpc@79024000";
		audio_clock = "/audio_clock";
		ad9361_clkin = "/clocks/clock@0";
		adf4351_clkin = "/clocks/clock@1";
	};
};
